# RP2350 register map
Vendor: Raspberry Pi; Series: RP; File version: 0.1
CPU: CM33 r1p0, little endian, MPU, FPU, DSP, VTOR, 4 interrupt priority bits, 52 interrupts, 8 SAU regions
Registers are 32-bit, read-write, reset 0x0 unless marked. A register's access mark holds for its fields unless they carry their own. Offsets are from the block's base; [hi:lo] are bit positions; {n}, {i} and the like mark numbered series; 'fields as' and 'values as' point back to an identical list; <NAME> marks a mode.

## OTP_DATA — Predefined OTP data layout for RP2350
Base 0x40130000
0x00 CHIPID0 16-bit reset not defined — Bits 15:0 of public device ID. (ECC) The CHIPID0..3 rows contain a 64-bit random identifier for this chip, which can be read from the USB bootloader PICOBOOT interface or from the get_sys_info ROM API. The number of random bits makes the occurrence of twins exceedingly unlikely: for example, a fleet of a hundred million devices has a 99.97% probability of no twinned IDs. This is estimated to be lower than the occurrence of process errors in the assignment of sequential random IDs, and for practical purposes CHIPID may be treated as unique.
  [15:0] CHIPID0 ro
{0x0+2i} CHIPID{i} 16-bit reset not defined (i=1..3) — Bits {16i+15}:{16i} of public device ID (ECC)
  [15:0] CHIPID{i} ro
0x08 RANDID0 16-bit reset not defined — Bits 15:0 of private per-device random number (ECC) The RANDID0..7 rows form a 128-bit random number generated during device test. This ID is not exposed through the USB PICOBOOT GET_INFO command or the ROM `get_sys_info()` API. However note that the USB PICOBOOT OTP access point can read the entirety of page 0, so this value is not meaningfully private unless the USB PICOBOOT interface is disabled via the DISABLE_BOOTSEL_USB_PICOBOOT_IFC flag in BOOT_FLAGS0.
  [15:0] RANDID0 ro
{0x8+2i} RANDID{i} 16-bit reset not defined (i=1..7) — Bits {16i+15}:{16i} of private per-device random number (ECC)
  [15:0] RANDID{i} ro
0x20 ROSC_CALIB 16-bit reset not defined — Ring oscillator frequency in kHz, measured during manufacturing (ECC) This is measured at 1.1 V, at room temperature, with the ROSC configuration registers in their reset state.
  [15:0] ROSC_CALIB ro
0x22 LPOSC_CALIB 16-bit reset not defined — Low-power oscillator frequency in Hz, measured during manufacturing (ECC) This is measured at 1.1V, at room temperature, with the LPOSC trim register in its reset state.
  [15:0] LPOSC_CALIB ro
0x30 NUM_GPIOS 16-bit reset not defined — The number of main user GPIOs (bank 0). Should read 48 in the QFN80 package, and 30 in the QFN60 package. (ECC)
  [7:0] NUM_GPIOS ro
0x6C INFO_CRC0 16-bit reset not defined — Lower 16 bits of CRC32 of OTP addresses 0x00 through 0x6b (polynomial 0x4c11db7, input reflected, output reflected, seed all-ones, final XOR all-ones) (ECC)
  [15:0] INFO_CRC0 ro
0x6E INFO_CRC1 16-bit reset not defined — Upper 16 bits of CRC32 of OTP addresses 0x00 through 0x6b (ECC)
  [15:0] INFO_CRC1 ro
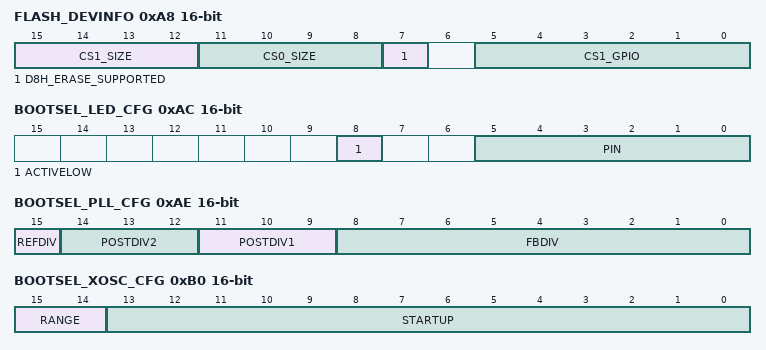
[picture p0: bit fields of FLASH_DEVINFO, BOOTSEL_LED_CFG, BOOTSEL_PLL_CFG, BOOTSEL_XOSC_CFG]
0xA8 FLASH_DEVINFO 16-bit — Stores information about external flash device(s). (ECC) Assumed to be valid if BOOT_FLAGS0_FLASH_DEVINFO_ENABLE is set.
  [15:12] CS1_SIZE ro — The size of the flash/PSRAM device on chip select 1 (addressable at 0x11000000 through 0x11ffffff). A value of zero is decoded as a size of zero (no device). Nonzero values are decoded as 4kiB << CS1_SIZE. For example, four megabytes is encoded with a CS1_SIZE value of 10, and 16 megabytes is encoded with a CS1_SIZE value of 12. When BOOT_FLAGS0_FLASH_DEVINFO_ENABLE is not set, a default of zero is used.
    0=NONE; 1=8K; 2=16K; 3=32K; 4=64k; 5=128K; 6=256K; 7=512K; 8=1M; 9=2M; 10=4M; 11=8M; 12=16M
  [11:8] CS0_SIZE ro — The size of the flash/PSRAM device on chip select 0 (addressable at 0x10000000 through 0x10ffffff). A value of zero is decoded as a size of zero (no device). Nonzero values are decoded as 4kiB << CS0_SIZE. For example, four megabytes is encoded with a CS0_SIZE value of 10, and 16 megabytes is encoded with a CS0_SIZE value of 12. When BOOT_FLAGS0_FLASH_DEVINFO_ENABLE is not set, a default of 12 (16 MiB) is used.
    values as CS1_SIZE
  [7] D8H_ERASE_SUPPORTED ro — If true, all attached devices are assumed to support (or ignore, in the case of PSRAM) a block erase command with a command prefix of D8h, an erase size of 64 kiB, and a 24-bit address. Almost all 25-series flash devices support this command. If set, the bootrom will use the D8h erase command where it is able, to accelerate bulk erase operations. This makes flash programming faster. When BOOT_FLAGS0_FLASH_DEVINFO_ENABLE is not set, this field defaults to false.
  [5:0] CS1_GPIO ro — Indicate a GPIO number to be used for the secondary flash chip select (CS1), which selects the external QSPI device mapped at system addresses 0x11000000 through 0x11ffffff. There is no such configuration for CS0, as the primary chip select has a dedicated pin. On RP2350 the permissible GPIO numbers are 0, 8, 19 and 47. Ignored if CS1_size is zero. If CS1_SIZE is nonzero, the bootrom will automatically configure this GPIO as a second chip select upon entering the flash boot path, or entering any other path that may use the QSPI flash interface, such as BOOTSEL mode (nsboot).
0xAA FLASH_PARTITION_SLOT_SIZE 16-bit reset not defined — Gap between partition table slot 0 and slot 1 at the start of flash (the default size is 4096 bytes) (ECC) Enabled by the OVERRIDE_FLASH_PARTITION_SLOT_SIZE bit in BOOT_FLAGS, the size is 4096 * (value + 1)
  [15:0] FLASH_PARTITION_SLOT_SIZE ro
0xAC BOOTSEL_LED_CFG 16-bit — Pin configuration for LED status, used by USB bootloader. (ECC) Must be valid if BOOT_FLAGS0_ENABLE_BOOTSEL_LED is set.
  [8] ACTIVELOW ro — LED is active-low. (Default: active-high.)
  [5:0] PIN ro — GPIO index to use for bootloader activity LED.
0xAE BOOTSEL_PLL_CFG 16-bit — Optional PLL configuration for BOOTSEL mode. (ECC) This should be configured to produce an exact 48 MHz based on the crystal oscillator frequency. User mode software may also use this value to calculate the expected crystal frequency based on an assumed 48 MHz PLL output. If no configuration is given, the crystal is assumed to be 12 MHz. The PLL frequency can be calculated as: PLL out = (XOSC frequency / (REFDIV+1)) x FBDIV / (POSTDIV1 x POSTDIV2) Conversely the crystal frequency can be calculated as: XOSC frequency = 48 MHz x (REFDIV+1) x (POSTDIV1 x POSTDIV2) / FBDIV (Note the +1 on REFDIV is because the value stored in this OTP location is the actual divisor value minus one.) Used if and only if ENABLE_BOOTSEL_NON_DEFAULT_PLL_XOSC_CFG is set in BOOT_FLAGS0. That bit should be set only after this row and BOOTSEL_XOSC_CFG are both correctly programmed.
  [15] REFDIV ro — PLL reference divisor, minus one. Programming a value of 0 means a reference divisor of 1. Programming a value of 1 means a reference divisor of 2 (for exceptionally fast XIN inputs)
  [14:12] POSTDIV2 ro — PLL post-divide 2 divisor, in the range 1..7 inclusive.
  [11:9] POSTDIV1 ro — PLL post-divide 1 divisor, in the range 1..7 inclusive.
  [8:0] FBDIV ro — PLL feedback divisor, in the range 16..320 inclusive.
0xB0 BOOTSEL_XOSC_CFG 16-bit — Non-default crystal oscillator configuration for the USB bootloader. (ECC) These values may also be used by user code configuring the crystal oscillator. Used if and only if ENABLE_BOOTSEL_NON_DEFAULT_PLL_XOSC_CFG is set in BOOT_FLAGS0. That bit should be set only after this row and BOOTSEL_PLL_CFG are both correctly programmed.
  [15:14] RANGE ro — Value of the XOSC_CTRL_FREQ_RANGE register.
    0=1_15MHZ; 1=10_30MHZ; 2=25_60MHZ; 3=40_100MHZ
  [13:0] STARTUP ro — Value of the XOSC_STARTUP register
0xB8 USB_WHITE_LABEL_ADDR 16-bit reset not defined — Row index of the USB_WHITE_LABEL structure within OTP (ECC) The table has 16 rows, each of which are also ECC and marked valid by the corresponding valid bit in USB_BOOT_FLAGS (ECC). The entries are either _VALUEs where the 16 bit value is used as is, or _STRDEFs which acts as a pointers to a string value. The value stored in a _STRDEF is two separate bytes: The low seven bits of the first (LSB) byte indicates the number of characters in the string, and the top bit of the first (LSB) byte if set to indicate that each character in the string is two bytes (Unicode) versus one byte if unset. The second (MSB) byte represents the location of the string data, and is encoded as the number of rows from this USB_WHITE_LABEL_ADDR; i.e. the row of the start of the string is USB_WHITE_LABEL_ADDR value + msb_byte. In each case, the corresponding valid bit enables replacing the default value for the corresponding item provided by the boot rom. Note that Unicode _STRDEFs are only supported for USB_DEVICE_PRODUCT_STRDEF, USB_DEVICE_SERIAL_NUMBER_STRDEF and USB_DEVICE_MANUFACTURER_STRDEF. Unicode values will be ignored if specified for other fields, and non-unicode values for these three items will be converted to Unicode characters by setting the upper 8 bits to zero. Note that if the USB_WHITE_LABEL structure or the corresponding strings are not readable by BOOTSEL mode based on OTP permissions, or if alignment requirements are not met, then the corresponding default values are used. The index values indicate where each field is located (row USB_WHITE_LABEL_ADDR value + index):
  [15:0] USB_WHITE_LABEL_ADDR ro
    0=INDEX_USB_DEVICE_VID_VALUE; 1=INDEX_USB_DEVICE_PID_VALUE; 2=INDEX_USB_DEVICE_BCD_DEVICE_VALUE; 3=INDEX_USB_DEVICE_LANG_ID_VALUE; 4=INDEX_USB_DEVICE_MANUFACTURER_STRDEF; 5=INDEX_USB_DEVICE_PRODUCT_STRDEF; 6=INDEX_USB_DEVICE_SERIAL_NUMBER_STRDEF; 7=INDEX_USB_CONFIG_ATTRIBUTES_MAX_POWER_VALUES; 8=INDEX_VOLUME_LABEL_STRDEF; 9=INDEX_SCSI_INQUIRY_VENDOR_STRDEF; 10=INDEX_SCSI_INQUIRY_PRODUCT_STRDEF; 11=INDEX_SCSI_INQUIRY_VERSION_STRDEF; 12=INDEX_INDEX_HTM_REDIRECT_URL_STRDEF; 13=INDEX_INDEX_HTM_REDIRECT_NAME_STRDEF; 14=INDEX_INFO_UF2_TXT_MODEL_STRDEF; 15=INDEX_INFO_UF2_TXT_BOARD_ID_STRDEF
0xBC OTPBOOT_SRC 16-bit reset not defined — OTP start row for the OTP boot image. (ECC) If OTP boot is enabled, the bootrom will load from this location into SRAM and then directly enter the loaded image. Note that the image must be signed if SECURE_BOOT_ENABLE is set. The image itself is assumed to be ECC-protected. This must be an even number. Equivalently, the OTP boot image must start at a word-aligned location in the ECC read data address window.
  [15:0] OTPBOOT_SRC ro
0xBE OTPBOOT_LEN 16-bit reset not defined — Length in rows of the OTP boot image. (ECC) OTPBOOT_LEN must be even. The total image size must be a multiple of 4 bytes (32 bits).
  [15:0] OTPBOOT_LEN ro
0xC0 OTPBOOT_DST0 16-bit reset not defined — Bits 15:0 of the OTP boot image load destination (and entry point). (ECC) This must be a location in main SRAM (main SRAM is addresses 0x20000000 through 0x20082000) and must be word-aligned.
  [15:0] OTPBOOT_DST0 ro
0xC2 OTPBOOT_DST1 16-bit reset not defined — Bits 31:16 of the OTP boot image load destination (and entry point). (ECC) This must be a location in main SRAM (main SRAM is addresses 0x20000000 through 0x20082000) and must be word-aligned.
  [15:0] OTPBOOT_DST1 ro
{0x100+0x40*i} BOOTKEY{i}_0 (i=0..3) 16-bit reset not defined — Bits 15:0 of SHA-256 hash of boot key 0 (ECC)
  [15:0] BOOTKEY_0 ro
{0x102+0x40*i} BOOTKEY{i}_1 (i=0..3) 16-bit reset not defined — Bits 31:16 of SHA-256 hash of boot key 0 (ECC)
  [15:0] BOOTKEY_1 ro
{0x104+0x40*i} BOOTKEY{i}_2 (i=0..3) 16-bit reset not defined — Bits 47:32 of SHA-256 hash of boot key 0 (ECC)
  [15:0] BOOTKEY_2 ro
{0x106+0x40*i} BOOTKEY{i}_3 (i=0..3) 16-bit reset not defined — Bits 63:48 of SHA-256 hash of boot key 0 (ECC)
  [15:0] BOOTKEY_3 ro
{0x108+0x40*i} BOOTKEY{i}_4 (i=0..3) 16-bit reset not defined — Bits 79:64 of SHA-256 hash of boot key 0 (ECC)
  [15:0] BOOTKEY_4 ro
{0x10A+0x40*i} BOOTKEY{i}_5 (i=0..3) 16-bit reset not defined — Bits 95:80 of SHA-256 hash of boot key 0 (ECC)
  [15:0] BOOTKEY_5 ro
{0x10C+0x40*i} BOOTKEY{i}_6 (i=0..3) 16-bit reset not defined — Bits 111:96 of SHA-256 hash of boot key 0 (ECC)
  [15:0] BOOTKEY_6 ro
{0x10E+0x40*i} BOOTKEY{i}_7 (i=0..3) 16-bit reset not defined — Bits 127:112 of SHA-256 hash of boot key 0 (ECC)
  [15:0] BOOTKEY_7 ro
{0x110+0x40*i} BOOTKEY{i}_8 (i=0..3) 16-bit reset not defined — Bits 143:128 of SHA-256 hash of boot key 0 (ECC)
  [15:0] BOOTKEY_8 ro
{0x112+0x40*i} BOOTKEY{i}_9 (i=0..3) 16-bit reset not defined — Bits 159:144 of SHA-256 hash of boot key 0 (ECC)
  [15:0] BOOTKEY_9 ro
{0x114+0x40*i} BOOTKEY{i}_10 (i=0..3) 16-bit reset not defined — Bits 175:160 of SHA-256 hash of boot key 0 (ECC)
  [15:0] BOOTKEY_10 ro
{0x116+0x40*i} BOOTKEY{i}_11 (i=0..3) 16-bit reset not defined — Bits 191:176 of SHA-256 hash of boot key 0 (ECC)
  [15:0] BOOTKEY_11 ro
{0x118+0x40*i} BOOTKEY{i}_12 (i=0..3) 16-bit reset not defined — Bits 207:192 of SHA-256 hash of boot key 0 (ECC)
  [15:0] BOOTKEY_12 ro
{0x11A+0x40*i} BOOTKEY{i}_13 (i=0..3) 16-bit reset not defined — Bits 223:208 of SHA-256 hash of boot key 0 (ECC)
  [15:0] BOOTKEY_13 ro
{0x11C+0x40*i} BOOTKEY{i}_14 (i=0..3) 16-bit reset not defined — Bits 239:224 of SHA-256 hash of boot key 0 (ECC)
  [15:0] BOOTKEY_14 ro
{0x11E+0x40*i} BOOTKEY{i}_15 (i=0..3) 16-bit reset not defined — Bits 255:240 of SHA-256 hash of boot key 0 (ECC)
  [15:0] BOOTKEY_15 ro
{0x1E70+0x20*i} KEY{i}_0 (i=1..6) 16-bit reset not defined — Bits 15:0 of OTP access key 1 (ECC)
  [15:0] KEY_0 ro
{0x1E72+0x20*i} KEY{i}_1 (i=1..6) 16-bit reset not defined — Bits 31:16 of OTP access key 1 (ECC)
  [15:0] KEY_1 ro
{0x1E74+0x20*i} KEY{i}_2 (i=1..6) 16-bit reset not defined — Bits 47:32 of OTP access key 1 (ECC)
  [15:0] KEY_2 ro
{0x1E76+0x20*i} KEY{i}_3 (i=1..6) 16-bit reset not defined — Bits 63:48 of OTP access key 1 (ECC)
  [15:0] KEY_3 ro
{0x1E78+0x20*i} KEY{i}_4 (i=1..6) 16-bit reset not defined — Bits 79:64 of OTP access key 1 (ECC)
  [15:0] KEY_4 ro
{0x1E7A+0x20*i} KEY{i}_5 (i=1..6) 16-bit reset not defined — Bits 95:80 of OTP access key 1 (ECC)
  [15:0] KEY_5 ro
{0x1E7C+0x20*i} KEY{i}_6 (i=1..6) 16-bit reset not defined — Bits 111:96 of OTP access key 1 (ECC)
  [15:0] KEY_6 ro
{0x1E7E+0x20*i} KEY{i}_7 (i=1..6) 16-bit reset not defined — Bits 127:112 of OTP access key 1 (ECC)
  [15:0] KEY_7 ro

## Notices in the file
Copyright (c) 2024 Raspberry Pi Ltd.
SPDX-License-Identifier: BSD-3-Clause
